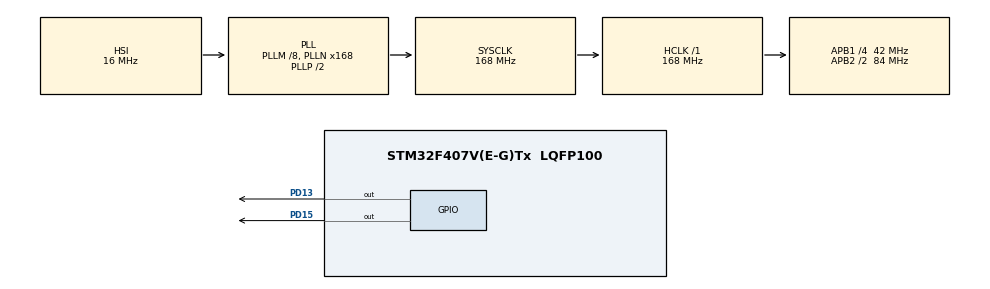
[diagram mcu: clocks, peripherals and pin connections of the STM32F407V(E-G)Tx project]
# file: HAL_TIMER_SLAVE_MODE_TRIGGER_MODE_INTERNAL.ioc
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Mcu.Family=STM32F4
Mcu.Name=STM32F407V(E-G)Tx
Mcu.Package=LQFP100
NVIC.PriorityGroup=NVIC_PRIORITYGROUP_4
NVIC.TIM2_IRQn=true\:0\:0\:false\:false\:true\:true\:true\:true
PD13.Signal=GPIO_Output
PD15.Signal=GPIO_Output
ProjectManager.HeapSize=0x200
ProjectManager.StackSize=0x400
ProjectManager.TargetToolchain=STM32CubeIDE
RCC.48MHZClocksFreq_Value=84000000
RCC.AHBFreq_Value=168000000
RCC.APB1CLKDivider=RCC_HCLK_DIV4
RCC.APB1Freq_Value=42000000
RCC.APB1TimFreq_Value=84000000
RCC.APB2CLKDivider=RCC_HCLK_DIV2
RCC.APB2Freq_Value=84000000
RCC.APB2TimFreq_Value=168000000
RCC.CortexFreq_Value=168000000
RCC.HCLKFreq_Value=168000000
RCC.HSE_VALUE=25000000
RCC.HSI_VALUE=16000000
RCC.LSE_VALUE=32768
RCC.PLLM=8
RCC.PLLN=168
RCC.SYSCLKFreq_VALUE=168000000
RCC.SYSCLKSource=RCC_SYSCLKSOURCE_PLLCLK
RCC.VCOOutputFreq_Value=336000000
TIM1.Period=4000-1
TIM1.Prescaler=42000-1
TIM1.TIM_MasterOutputTrigger=TIM_TRGO_UPDATE
TIM1.TIM_MasterSlaveMode=TIM_MASTERSLAVEMODE_ENABLE
TIM2.Period=1000-1
TIM2.Prescaler=42000-1
VP_TIM1_VS_ClockSourceINT.Mode=Internal
VP_TIM2_VS_ClockSourceINT.Mode=Internal
VP_TIM2_VS_ClockSourceITR.Mode=TriggerSource_ITR0
VP_TIM2_VS_ControllerModeTrigger.Mode=Trigger Mode
board=custom

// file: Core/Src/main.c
/* USER CODE BEGIN Header */
/**
  ******************************************************************************
  * @file           : main.c
  * @brief          : Main program body
  ******************************************************************************
  * @attention
  *
  * Copyright (c) 2024 STMicroelectronics.
  * All rights reserved.
  *
  * This software is licensed under terms that can be found in the LICENSE file
  * in the root directory of this software component.
  * If no LICENSE file comes with this software, it is provided AS-IS.
  *
  ******************************************************************************
  */
/* USER CODE END Header */
#include "main.h"

TIM_HandleTypeDef htim1;
TIM_HandleTypeDef htim2;

/* USER CODE BEGIN PV */
uint32_t count_TIM1=0,count_TIM2=0;
/* USER CODE END PV */

void SystemClock_Config(void);
static void MX_GPIO_Init(void);
static void MX_TIM1_Init(void);
static void MX_TIM2_Init(void);

int main(void)
{

  /* MCU Configuration--------------------------------------------------------*/

  /* Reset of all peripherals, Initializes the Flash interface and the Systick. */
  HAL_Init();

  /* Configure the system clock */
  SystemClock_Config();

  /* Initialize all configured peripherals */
  MX_GPIO_Init();
  MX_TIM1_Init();
  MX_TIM2_Init();
  /* USER CODE BEGIN 2 */

  // we must start only TIM1 because it starts TIM2
  HAL_TIM_Base_Start(&htim1);

  __HAL_TIM_CLEAR_FLAG(&htim2,TIM_FLAG_UPDATE);

  // i filled the interrupt function in stm32f4xx_it.c
  // Check there if you are confused

  /* USER CODE END 2 */

  /* Infinite loop */
  /* USER CODE BEGIN WHILE */
  while (1)
  {

	  count_TIM1 = __HAL_TIM_GET_COUNTER(&htim1);
	  count_TIM2 = __HAL_TIM_GET_COUNTER(&htim2);

	  if(__HAL_TIM_GET_FLAG(&htim2,TIM_FLAG_TRIGGER))
	  {
		HAL_GPIO_TogglePin(GPIOD, GPIO_PIN_13);
		__HAL_TIM_ENABLE_IT(&htim2,TIM_FLAG_UPDATE);
		__HAL_TIM_CLEAR_FLAG(&htim2,TIM_FLAG_TRIGGER);
	  }

    /* USER CODE END WHILE */

  }
}

void SystemClock_Config(void)
{
  RCC_OscInitTypeDef RCC_OscInitStruct = {0};
  RCC_ClkInitTypeDef RCC_ClkInitStruct = {0};

  /** Configure the main internal regulator output voltage
  */
  __HAL_RCC_PWR_CLK_ENABLE();
  __HAL_PWR_VOLTAGESCALING_CONFIG(PWR_REGULATOR_VOLTAGE_SCALE1);

  /** Initializes the RCC Oscillators according to the specified parameters
  * in the RCC_OscInitTypeDef structure.
  */
  RCC_OscInitStruct.OscillatorType = RCC_OSCILLATORTYPE_HSI;
  RCC_OscInitStruct.HSIState = RCC_HSI_ON;
  RCC_OscInitStruct.HSICalibrationValue = RCC_HSICALIBRATION_DEFAULT;
  RCC_OscInitStruct.PLL.PLLState = RCC_PLL_ON;
  RCC_OscInitStruct.PLL.PLLSource = RCC_PLLSOURCE_HSI;
  RCC_OscInitStruct.PLL.PLLM = 8;
  RCC_OscInitStruct.PLL.PLLN = 168;
  RCC_OscInitStruct.PLL.PLLP = RCC_PLLP_DIV2;
  RCC_OscInitStruct.PLL.PLLQ = 4;
  if (HAL_RCC_OscConfig(&RCC_OscInitStruct) != HAL_OK)
  {
    Error_Handler();
  }

  /** Initializes the CPU, AHB and APB buses clocks
  */
  RCC_ClkInitStruct.ClockType = RCC_CLOCKTYPE_HCLK|RCC_CLOCKTYPE_SYSCLK
                              |RCC_CLOCKTYPE_PCLK1|RCC_CLOCKTYPE_PCLK2;
  RCC_ClkInitStruct.SYSCLKSource = RCC_SYSCLKSOURCE_PLLCLK;
  RCC_ClkInitStruct.AHBCLKDivider = RCC_SYSCLK_DIV1;
  RCC_ClkInitStruct.APB1CLKDivider = RCC_HCLK_DIV4;
  RCC_ClkInitStruct.APB2CLKDivider = RCC_HCLK_DIV2;

  if (HAL_RCC_ClockConfig(&RCC_ClkInitStruct, FLASH_LATENCY_5) != HAL_OK)
  {
    Error_Handler();
  }
}

static void MX_TIM1_Init(void)
{

  TIM_ClockConfigTypeDef sClockSourceConfig = {0};
  TIM_MasterConfigTypeDef sMasterConfig = {0};

  htim1.Instance = TIM1;
  htim1.Init.Prescaler = 42000-1;
  htim1.Init.CounterMode = TIM_COUNTERMODE_UP;
  htim1.Init.Period = 4000-1;
  htim1.Init.ClockDivision = TIM_CLOCKDIVISION_DIV1;
  htim1.Init.RepetitionCounter = 0;
  htim1.Init.AutoReloadPreload = TIM_AUTORELOAD_PRELOAD_DISABLE;
  if (HAL_TIM_Base_Init(&htim1) != HAL_OK)
  {
    Error_Handler();
  }
  sClockSourceConfig.ClockSource = TIM_CLOCKSOURCE_INTERNAL;
  if (HAL_TIM_ConfigClockSource(&htim1, &sClockSourceConfig) != HAL_OK)
  {
    Error_Handler();
  }
  sMasterConfig.MasterOutputTrigger = TIM_TRGO_UPDATE;
  sMasterConfig.MasterSlaveMode = TIM_MASTERSLAVEMODE_ENABLE;
  if (HAL_TIMEx_MasterConfigSynchronization(&htim1, &sMasterConfig) != HAL_OK)
  {
    Error_Handler();
  }

}

static void MX_TIM2_Init(void)
{

  TIM_ClockConfigTypeDef sClockSourceConfig = {0};
  TIM_SlaveConfigTypeDef sSlaveConfig = {0};
  TIM_MasterConfigTypeDef sMasterConfig = {0};

  htim2.Instance = TIM2;
  htim2.Init.Prescaler = 42000-1;
  htim2.Init.CounterMode = TIM_COUNTERMODE_UP;
  htim2.Init.Period = 1000-1;
  htim2.Init.ClockDivision = TIM_CLOCKDIVISION_DIV1;
  htim2.Init.AutoReloadPreload = TIM_AUTORELOAD_PRELOAD_DISABLE;
  if (HAL_TIM_Base_Init(&htim2) != HAL_OK)
  {
    Error_Handler();
  }
  sClockSourceConfig.ClockSource = TIM_CLOCKSOURCE_INTERNAL;
  if (HAL_TIM_ConfigClockSource(&htim2, &sClockSourceConfig) != HAL_OK)
  {
    Error_Handler();
  }
  sSlaveConfig.SlaveMode = TIM_SLAVEMODE_TRIGGER;
  sSlaveConfig.InputTrigger = TIM_TS_ITR0;
  if (HAL_TIM_SlaveConfigSynchro(&htim2, &sSlaveConfig) != HAL_OK)
  {
    Error_Handler();
  }
  sMasterConfig.MasterOutputTrigger = TIM_TRGO_RESET;
  sMasterConfig.MasterSlaveMode = TIM_MASTERSLAVEMODE_DISABLE;
  if (HAL_TIMEx_MasterConfigSynchronization(&htim2, &sMasterConfig) != HAL_OK)
  {
    Error_Handler();
  }

}

static void MX_GPIO_Init(void)
{
  GPIO_InitTypeDef GPIO_InitStruct = {0};

  /* GPIO Ports Clock Enable */
  __HAL_RCC_GPIOD_CLK_ENABLE();

  /*Configure GPIO pin Output Level */
  HAL_GPIO_WritePin(GPIOD, GPIO_PIN_13|GPIO_PIN_15, GPIO_PIN_RESET);

  /*Configure GPIO pins : PD13 PD15 */
  GPIO_InitStruct.Pin = GPIO_PIN_13|GPIO_PIN_15;
  GPIO_InitStruct.Mode = GPIO_MODE_OUTPUT_PP;
  GPIO_InitStruct.Pull = GPIO_NOPULL;
  GPIO_InitStruct.Speed = GPIO_SPEED_FREQ_LOW;
  HAL_GPIO_Init(GPIOD, &GPIO_InitStruct);

}

void Error_Handler(void)
{
  __disable_irq();
  while (1)
  {
  }
}
